# STM32F401 register map
Vendor: STMicroelectronics; File version: 1.8
STM32F401 (trimmed)
CPU: CM4 r0p1, little endian
Registers are 32-bit, access not given, reset 0x0 unless marked. A register's access mark holds for its fields unless they carry their own. Offsets are from the block's base; lines under a group give offsets from that group; [hi:lo] are bit positions; {n}, {i} and the like mark numbered series; 'fields as' and 'values as' point back to an identical list; <NAME> marks a mode.

## Memory map
0x40000000 TIM2 — General purpose timers
0x40004400 USART2 — Universal synchronous asynchronous receiver transmitter
0x40020000 GPIOA size 0x400 — General-purpose I/Os
0x40020400 GPIOB size 0x400
0x40023800 RCC — Reset and clock control

## GPIOA — General-purpose I/Os
Base 0x40020000
Same registers: GPIOB 0x40020400
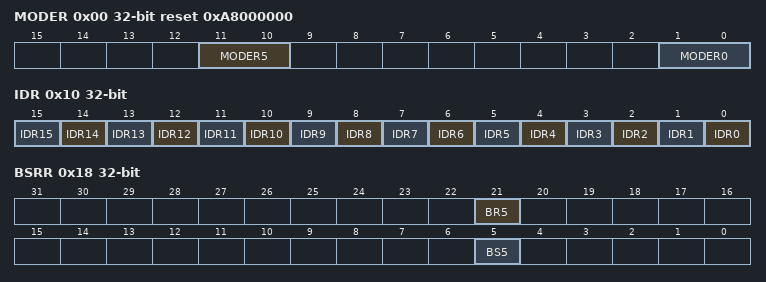
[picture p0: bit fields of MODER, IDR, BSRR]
0x00 MODER rw reset 0xA8000000 — GPIO port mode register
  [11:10] MODER5 — Port x configuration bits (y = 0..15)
    0=Input mode (reset state); 1=Output (General purpose output mode); 2=Alternate function mode; 3=Analog mode
  [1:0] MODER0 — Port x configuration bits (y = 0..15)
0x10 IDR ro — GPIO port input data register
  [n] IDR{n} (n=0..15) — Port input data (y = 0..15)
0x14 ODR — GPIO port output data register
  [5] ODR5 — Port output data (y = 5)
0x18 BSRR wo — GPIO port bit set/reset register
  [21] BR5, [5] BS5

## RCC — Reset and clock control
Base 0x40023800
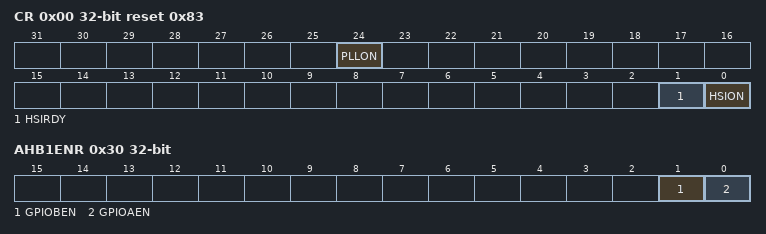
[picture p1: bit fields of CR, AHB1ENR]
0x00 CR reset 0x83 — clock control register
  [24] PLLON — Main PLL enable
  [1] HSIRDY ro — Internal high-speed clock ready flag
  [0] HSION — Internal high-speed clock enable
0x30 AHB1ENR — AHB1 peripheral clock enable register
  [1] GPIOBEN, [0] GPIOAEN

## USART2 — Universal synchronous asynchronous receiver transmitter
Base 0x40004400
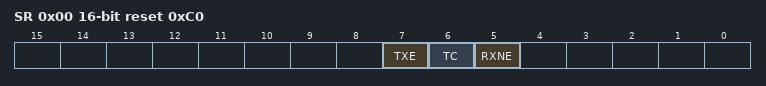
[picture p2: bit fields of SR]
0x00 SR 16-bit reset 0xC0 — Status register
  [7] TXE — Transmit data register empty
  [6] TC — Transmission complete
  [5] RXNE — Read data register not empty
0x04 DR 16-bit — Data register
  [8:0] DR

## TIM2 — General purpose timers
Base 0x40000000
{0x30+4i} CCR{i} (i=1..4) — capture/compare register
  [31:0] CCR
0x48 DMA group — DMA settings
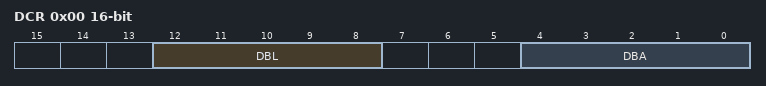
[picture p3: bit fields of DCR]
  0x00 DCR 16-bit — DMA control register
    [12:8] DBL, [4:0] DBA
  0x04 DMAR — DMA address for full transfer
